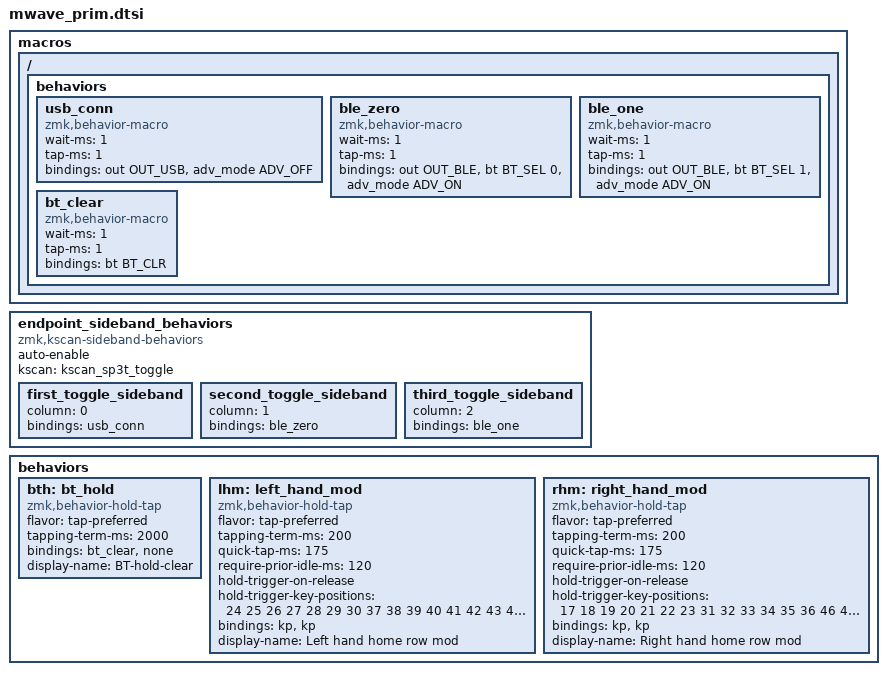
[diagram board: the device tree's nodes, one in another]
macros {
    ZMK_MACRO(usb_conn,
        wait-ms = <1>;
        tap-ms = <1>;
        bindings = <&out OUT_USB &adv_mode ADV_OFF>;
    )
    ZMK_MACRO(ble_zero,
        wait-ms = <1>;
        tap-ms = <1>;
        bindings = <&out OUT_BLE &bt BT_SEL 0 &adv_mode ADV_ON>;
    )
    ZMK_MACRO(ble_one,
        wait-ms = <1>;
        tap-ms = <1>;
        bindings = <&out OUT_BLE &bt BT_SEL 1 &adv_mode ADV_ON>;
    )
    ZMK_MACRO(bt_clear,
        wait-ms = <1>;
        tap-ms = <1>;
        bindings = <&bt BT_CLR>;
    )
    #include "version.dtsi"
};

endpoint_sideband_behaviors {
    auto-enable;
    compatible = "zmk,kscan-sideband-behaviors";
    kscan = <&kscan_sp3t_toggle>;

    first_toggle_sideband: first_toggle_sideband {
        column = <0>;
        bindings = <&usb_conn>;
    };

    second_toggle_sideband: second_toggle_sideband {
        column = <1>;
        bindings = <&ble_zero>;
    };

    third_toggle_sideband: third_toggle_sideband {
        column = <2>;
        bindings = <&ble_one>;
    };
};

behaviors {
    bth: bt_hold {
        compatible = "zmk,behavior-hold-tap";
        #binding-cells = <2>;
        flavor = "tap-preferred";
        tapping-term-ms = <2000>;
        bindings = <&bt_clear>, <&none>;
        display-name = "BT-hold-clear";
    };

    lhm: left_hand_mod {
        compatible = "zmk,behavior-hold-tap";
        #binding-cells = <2>;

        /* Prefer taps while typing */
        flavor = "tap-preferred";

        /* Good starting values for HRM */
        tapping-term-ms = <200>;
        quick-tap-ms = <175>;
        require-prior-idle-ms = <120>;

        /* Key improvement for positional HRMs */
        hold-trigger-on-release;

        /* If the next keypress is on the RIGHT side, allow the hold (mod) */
        hold-trigger-key-positions = <
            24 25 26 27 28 29 30
            37 38 39 40 41 42 43 44 45
            52 53 54 55 56 57 58 59
            66 67 68 69 70 71 72 73
            78 79 80 81 82 83 84
        >;

        bindings = <&kp &kp>;
        display-name = "Left hand home row mod";
    };

    rhm: right_hand_mod {
        compatible = "zmk,behavior-hold-tap";
        #binding-cells = <2>;

        flavor = "tap-preferred";
        tapping-term-ms = <200>;
        quick-tap-ms = <175>;
        require-prior-idle-ms = <120>;

        hold-trigger-on-release;

        /* If the next keypress is on the LEFT side, allow the hold (mod) */
        hold-trigger-key-positions = <
            17 18 19 20 21 22 23
            31 32 33 34 35 36
            46 47 48 49 50 51
            60 61 62 63 64 65
            74 75 76 77
        >;

        bindings = <&kp &kp>;
        display-name = "Right hand home row mod";
    };
};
